# myChip register map
Vendor: ARM Ltd.; Series: ARMCM3; File version: 1.2
CPU: CM3 r2p1, little endian, no MPU, no FPU, 3 interrupt priority bits
Registers are 32-bit, read-write, reset 0x0 unless marked. A register's access mark holds for its fields unless they carry their own. Offsets are from the block's base; [hi:lo] are bit positions.

## I2C0
Base 0x40000000
Same registers: I2C1 0x40001000, I2C2 0x40002000
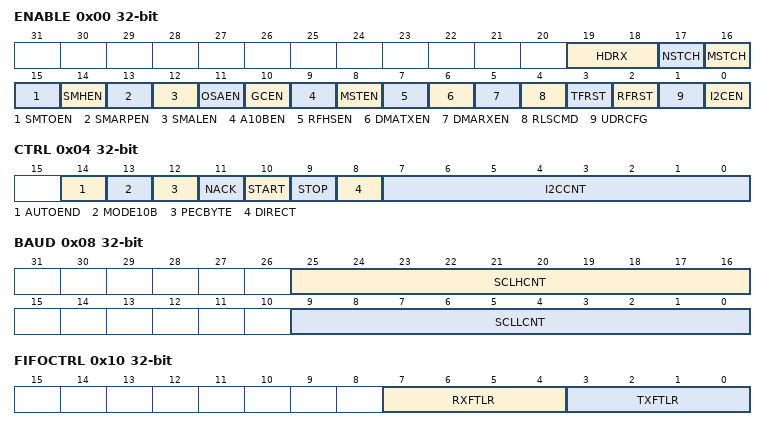
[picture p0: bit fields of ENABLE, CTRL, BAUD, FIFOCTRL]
0x00 ENABLE — I2C Enable Register
  [19:18] HDRX ro — I2C总线状态（I2C Bus Status）
  [17] NSTCH — I2C时钟延长禁止位（I2C SCL Stretching Disable）
  [16] MSTCH — I2C时钟延长模式位（I2C SCL Stretching Mode）
  [15] SMTOEN — SMBUS超时功能使能（SMBUS Timeout Enable）
  [14] SMHEN — SMBUS HOST地址使能位（SMBUS Host Address Enable）
  [13] SMARPEN — SMBUS设备默认地址使能位（SMBUS Device Default Address Enable）
  [12] SMALEN — SMBUS报警功能使能位（SMBUS Alert Enable）
  [11] OSAEN — I2C可选从机地址使能（I2C Optional Slave Address Register）
  [10] GCEN — I2C广播地址使能位（I2C General Call Address Enable）
  [9] A10BEN — I2C 10BIT地址使能位（I2C 10BIT Address Enable）
  [8] MSTEN ro — I2C主机状态位（I2C Master Status）
  [7] RFHSEN — I2C接收数据时钟延长模式位（I2C Receive Date SCL Stretching Mode）
  [6] DMATXEN — I2C发送DMA使能位（I2C TX-DMA Enable）
  [5] DMARXEN — I2C接收DMA使能位（I2C RX-DMA Enable）
  [4] RLSCMD — I2C启动传输命令（I2C Release Command）
  [3] TFRST — I2C TXFIFO复位（TXFIFO Reset Flag）
  [2] RFRST — I2C RXFIFO复位（RXFIFO Reset Flag）
  [1] UDRCFG — I2C下溢条件时从机发送行为（I2C Behavior At Slave Underrun Condition）
  [0] I2CEN — I2C使能位（I2C Enable）
0x04 CTRL — I2C Transmission Control Register
  [14] AUTOEND — I2C自动结束模式（I2C Automatic End Mode）
  [13] MODE10B — I2C 10BIT传输模式选择（I2C 10BIT Master-Read Mode Select）
  [12] PECBYTE — SMBUS数据包错误校验字节（SMBUS Packet Error Checking Byte）
  [11] NACK — I2C NACK生成（I2C NACK Generation）
  [10] START — I2C START生成（I2C START Generation）
  [9] STOP — I2C停止传输（I2C Stop Transmission）
  [8] DIRECT — I2C传输方向（I2C Direct Configuration）
  [7:0] I2CCNT — I2C传输字节数（I2C Number Of Data Byte Count）
0x08 BAUD — I2C Baud Rate Register
  [25:16] SCLHCNT — I2C SCL高电平周期（I2C SCL High Period）
  [9:0] SCLLCNT — I2C SCL低电平周期（I2C SCL Low Period）
0x0C UDRDR — I2C Underrun Data Register
  [7:0] UDRDR — I2C从模式下溢时数据写寄存器（I2C Data At Slave Underrun Condition）
0x10 FIFOCTRL — I2C FIFO Control Register
  [7:4] RXFTLR — I2C RXFIFO满中断阈值（I2C RXFIFO Full Threshold）
  [3:0] TXFTLR — I2C TXFIFO空中断阈值（I2C TXFIFO Empty Threshold）
0x14 TAR — I2C Target Address Register
  [9:0] TAR — I2C主机目标地址（I2C Target Address）
0x18 SAR — I2C Slave Address Register
  [9:0] SAR — I2C从机地址（I2C Slave Address）
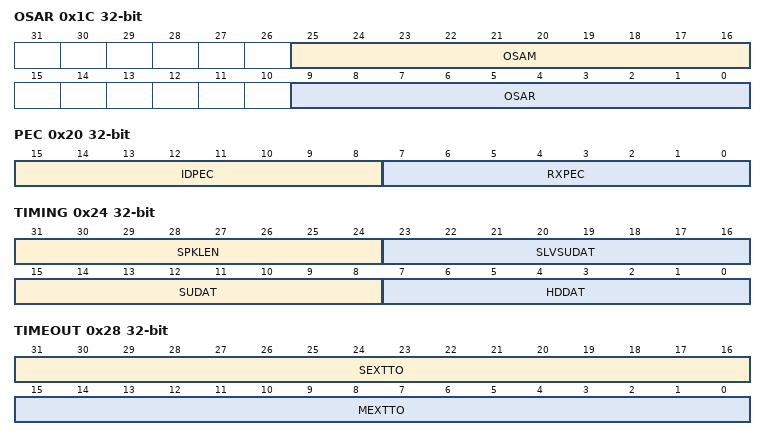
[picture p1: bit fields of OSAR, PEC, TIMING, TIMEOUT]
0x1C OSAR — I2C Optional Slave Address Register
  [25:16] OSAM — I2C可选的从机地址屏蔽（I2C Optional Slave Address Masks Register）
  [9:0] OSAR — I2C可选的从机地址（I2C Optional Slave Address Register）
0x20 PEC — I2C RX PEC Register
  [15:8] IDPEC ro — SMBUS自身PEC数据寄存器（SMBUS ID PEC Data Register）
  [7:0] RXPEC ro — SMBUS接收PEC数据寄存器（SMBUS RX PEC Data Register）
0x24 TIMING — I2C Timing Register
  [31:24] SPKLEN — I2C尖峰抑制寄存器（I2C Spike Suppression Limit Register）
  [23:16] SLVSUDAT — I2C从机数据建立时间（I2C Data Setup Time）
  [15:8] SUDAT — I2C数据建立时间（Data Setup Time）
  [7:0] HDDAT — I2C数据保持时间（Data Hold Time）
0x28 TIMEOUT — I2C Clock Extension Timeout Register
  [31:16] SEXTTO — I2C从机时钟扩展超时（I2C Slave Clock Extension Timeout Register）
  [15:0] MEXTTO — I2C主机时钟扩展超时（I2C Master Clock Extension Timeout Register）
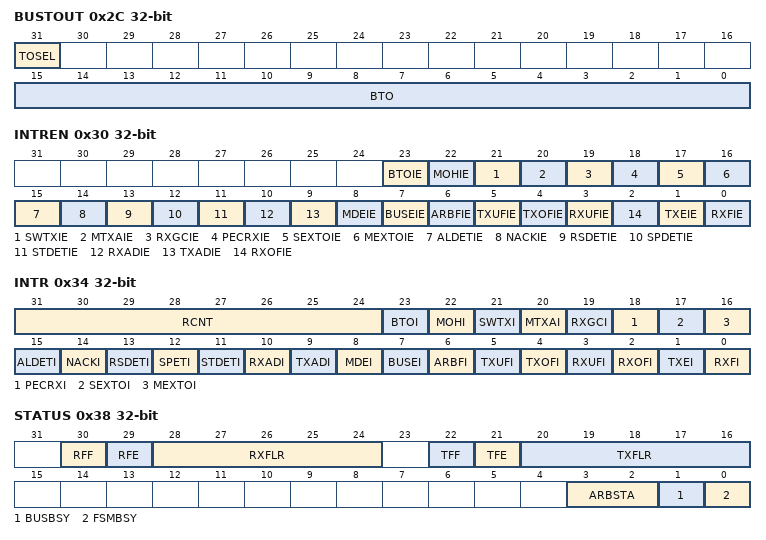
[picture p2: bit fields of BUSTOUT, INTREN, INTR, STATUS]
0x2C BUSTOUT — I2C Bus Timeout Register
  [31] TOSEL — I2C空闲时钟超时选择（I2C Clock Timeout Select）
  [15:0] BTO — I2C总线超时（I2C Bus Timeout）
0x30 INTREN — I2C Interrupt Enable Register
  [23] BTOIE — I2C 总线超时中断使能（I2C Bus Timeout Interrupt Enable）
  [22] MOHIE — I2C主机挂起拉住SCL为低中断使能（I2C Master Hold SCL Low Interrupt Enable）
  [21] SWTXIE — I2C从机等待数据拉住SCL为低中断使能（I2C Slave Hold SCL Low For Waiting Data Interrupt Enable）
  [20] MTXAIE — I2C主机发送地址完成中断使能（Master TX Adderss Done Interrupt Enable）
  [19] RXGCIE — I2C从机接收广播地址中断使能（Slave RX General Call Interrupt Enable）
  [18] PECRXIE — I2C收到PEC且校验错误中断使能（I2C Received PEC Byte With Checksum Error Interrupt Enable）
  [17] SEXTOIE — I2C Tsext超时中断使能（I2C Slave Detected Timeout Interrupt Enable）
  [16] MEXTOIE — I2C Tmext超时中断使能（I2C Master Detected Timeout Interrupt Enable）
  [15] ALDETIE — I2C检测到SBA信号中断使能（I2C Detected SBA Signal Interrupt Enable）
  [14] NACKIE — I2C检测到NACK位中断使能（I2C Detected NACK Interrupt Enable）
  [13] RSDETIE — I2C检测到RESTART位中断使能（I2C Detected RESTART Interrupt Enable）
  [12] SPDETIE — I2C检测到STOP位中断使能（I2C Detected STOP Interrupt Enable）
  [11] STDETIE — I2C检测到START位中断使能（I2C Detected START/RESTART Interrupt Enable）
  [10] RXADIE — I2C从机地址匹配接收中断使能（I2C Slave RX Address Matching Interrupt Enable）
  [9] TXADIE — I2C从机地址匹配发送中断使能（I2C Slave Tx Address Matching Interrupt Enable）
  [8] MDEIE — I2C传输完成中断使能（I2C Transmission Done Interrupt Enable）
  [7] BUSEIE — I2C总线错误中断使能（I2C Bus Error Interrupt Enable）
  [6] ARBFIE — I2C仲裁失败中断使能（I2C Arbitration Fail Interrupt Enable）
  [5] TXUFIE — I2C 从机TXFIFO下溢中断使能（I2C Slave TXFIFO Underflow Interrupt Enable）
  [4] TXOFIE — I2C TXFIFO上溢中断使能（I2C TXFIFO Overflow Interrupt Enable）
  [3] RXUFIE — I2C RXFIFO下溢中断使能（I2C RXFIFO Underflow Interrupt Enable）
  [2] RXOFIE — I2C RXFIFO上溢中断使能（I2C RXFIFO Overflow Interrupt Enable）
  [1] TXEIE — I2C TXFIFO空阈值中断使能（I2C TXFIFO Empty Threshold Interrupt Enable）
  [0] RXFIE — I2C RXFIFO满阈值中断使能（I2C RXFIFO Full Threshold Interrupt Enable）
0x34 INTR — I2C Interrupt Register
  [31:24] RCNT ro — I2C剩余数据计数状态（I2C Remain Data Count Status）
  [23] BTOI — I2C 总线超时中断（I2C Bus Timeout Interrupt）
  [22] MOHI ro — I2C主机挂起拉住SCL为低中断（I2C Master Hold SCL Low Interrupt）
  [21] SWTXI — I2C从机等待数据拉住SCL为低中断（I2C Slave Hold SCL Low For Waiting Data Interrupt）
  [20] MTXAI — 主机发送地址完成中断（Master TX Adderss Done Interrupt ）
  [19] RXGCI — 从机收到广播中断（Slave RX General Call Interrupt ）
  [18] PECRXI — I2C收到PEC且校验错误中断（I2C Received PEC Byte with Checksum Error Interrupt）
  [17] SEXTOI — I2C Tsext超时中断（I2C Slave Detected Timeout Interrupt）
  [16] MEXTOI — I2C Tmext超时中断（I2C Master Detected Timeout Interrupt）
  [15] ALDETI — I2C检测到SBA信号中断（I2C Detected SBA Signal Interrupt）
  [14] NACKI — I2C检测到NACK位中断（I2C Detected NACK Interrupt）
  [13] RSDETI — I2C检测到RESTART位中断（I2C Detected RESTART Interrupt）
  [12] SPETI — I2C检测到STOP位中断（I2C Detected STOP Interrupt）
  [11] STDETI — I2C检测到START位中断（I2C Detected START/RESTART Interrupt）
  [10] RXADI — I2C从机地址匹配接收中断（I2C Slave RX Address Matching Interrupt）
  [9] TXADI — I2C从机地址匹配发送中断（I2C Slave TX Address Matching Interrupt）
  [8] MDEI — I2C传输完成中断（I2C Transmission Done Interrupt）
  [7] BUSEI — I2C总线错误中断（I2C Bus Error Interrupt）
  [6] ARBFI — I2C仲裁失败中断（I2C Arbitration Fail Interrupt）
  [5] TXUFI — I2C 从机TXFIFO下溢中断（I2C Slave TXFIFO Underflow Interrupt）
  [4] TXOFI — I2C TXFIFO上溢中断（I2C TXFIFO Overflow Interrupt）
  [3] RXUFI — I2C RXFIFO下溢中断（I2C RXFIFO Underflow Interrupt）
  [2] RXOFI — I2C RXFIFO上溢中断（I2C RXFIFO Overflow Interrupt）
  [1] TXEI ro — I2C TXFIFO空阈值中断（I2C TXFIFO Empty Threshold Interrupt）
  [0] RXFI ro — I2C RXFIFO满阈值中断（I2C RXFIFO Full Threshold Interrupt）
0x38 STATUS — I2C Status Register
  [30] RFF ro — I2C RXFIFO满标志（I2C RXFIFO Full Status）
  [29] RFE ro — I2C RXFIFO空标志（I2C RXFIFO Empty Status）
  [28:24] RXFLR ro — I2C RXFIFO剩余数据量（I2C RXFIFO Remaining Data Number Status）
  [22] TFF ro — I2C TXFIFO满标志（I2C TXFIFO Full Status）
  [21] TFE ro — I2C TXFIFO空标志（I2C TXFIFO Empty Status）
  [20:16] TXFLR ro — I2C TXFIFO剩余数据量（I2C TXFIFO Remaining Data Number Status）
  [3:2] ARBSTA ro — I2C仲裁失败状态（I2C Arbitration Fail Status）
  [1] BUSBSY ro — I2C总线忙碌状态（I2C Bus Busy Status）
  [0] FSMBSY ro — I2C状态机忙碌状态（I2C State Busy Status）
0x40 TXDATA — I2C TXFIFO Data Registers
  [7:0] TXDATA — I2C数据写寄存器（I2C Data For Transmiting Register）
0x44 RXDATA — I2C RXFIFO Data Registers
  [7:0] RXDATA ro — I2C数据读寄存器（I2C Data For Receiving Register）
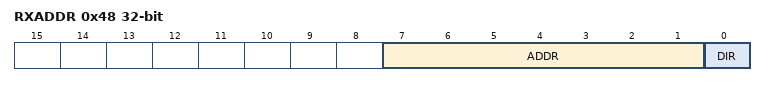
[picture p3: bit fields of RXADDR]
0x48 RXADDR — I2C RX ADDR Register
  [7:1] ADDR ro — I2C从机收到的地址（I2C Slave Received Address Status）
  [0] DIR ro — I2C从机收到的传输方向（I2C Slave Received Direction Status）
